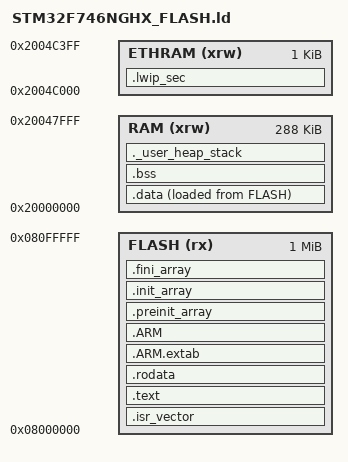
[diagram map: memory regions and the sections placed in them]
/*
******************************************************************************
**
** @file        : LinkerScript.ld
**
** @author      : Auto-generated by STM32CubeIDE
**
**  Abstract    : Linker script for STM32F746G-DISCO Board embedding STM32F746NGHx Device from stm32f7 series
**                      1024KBytes FLASH
**                      320KBytes RAM
**
**                Set heap size, stack size and stack location according
**                to application requirements.
**
**                Set memory bank area and size if external memory is used
**
**  Target      : STMicroelectronics STM32
**
**  Distribution: The file is distributed as is, without any warranty
**                of any kind.
**
******************************************************************************
** @attention
**
** Copyright (c) 2026 STMicroelectronics.
** All rights reserved.
**
** This software is licensed under terms that can be found in the LICENSE file
** in the root directory of this software component.
** If no LICENSE file comes with this software, it is provided AS-IS.
**
******************************************************************************
*/

/* Entry Point */
ENTRY(Reset_Handler)

/* Highest address of the user mode stack */
/* Main stack (MSP: startup + ISRs) stays at the very top of SRAM2 and grows
   down toward the ETH descriptors at 0x2004C000 (~15 KB of headroom, same
   layout as ST's LwIP examples). Kept OUT of the linker regions below. */
_estack = 0x20050000;

_Min_Heap_Size = 0x1000; /* required amount of heap (printf/newlib under FreeRTOS) */
_Min_Stack_Size = 0x400; /* required amount of stack */

/* Memories definition.
   The top 32 KB of the 320 KB RAM are reserved outside the linker regions:
     0x20048000..0x2004BFFF  LwIP heap (LWIP_RAM_HEAP_POINTER, MPU
                             non-cacheable so ETH DMA reads TX pbufs
                             coherently with the D-cache enabled)
     0x2004C000..0x2004C3FF  ETH DMA descriptors (ETHRAM below, MPU device)
     0x2004C400..0x2004FFFF  main stack (MSP), growing down from _estack */
MEMORY
{
  RAM    (xrw)    : ORIGIN = 0x20000000,   LENGTH = 288K
  ETHRAM (xrw)    : ORIGIN = 0x2004C000,   LENGTH = 1K
  FLASH    (rx)    : ORIGIN = 0x8000000,   LENGTH = 1024K
}

/* Sections */
SECTIONS
{

  /* The startup code into "FLASH" Rom type memory */
  .isr_vector :
  {
    . = ALIGN(4);
    KEEP(*(.isr_vector)) /* Startup code */
    . = ALIGN(4);
  } >FLASH

  /* The program code and other data into "FLASH" Rom type memory */
  .text :
  {
    . = ALIGN(4);
    *(.text)           /* .text sections (code) */
    *(.text*)          /* .text* sections (code) */
    *(.glue_7)         /* glue arm to thumb code */
    *(.glue_7t)        /* glue thumb to arm code */
    *(.eh_frame)

    KEEP (*(.init))
    KEEP (*(.fini))

    . = ALIGN(4);
    _etext = .;        /* define a global symbols at end of code */
  } >FLASH

  /* Constant data into "FLASH" Rom type memory */
  .rodata :
  {
    . = ALIGN(4);
    *(.rodata)         /* .rodata sections (constants, strings, etc.) */
    *(.rodata*)        /* .rodata* sections (constants, strings, etc.) */
    . = ALIGN(4);
  } >FLASH

  .ARM.extab (READONLY) : /* The "READONLY" keyword is only supported in GCC11 and later, remove it if using GCC10 or earlier. */
  {
    . = ALIGN(4);
    *(.ARM.extab* .gnu.linkonce.armextab.*)
    . = ALIGN(4);
  } >FLASH

  .ARM (READONLY) : /* The "READONLY" keyword is only supported in GCC11 and later, remove it if using GCC10 or earlier. */
  {
    . = ALIGN(4);
    __exidx_start = .;
    *(.ARM.exidx*)
    __exidx_end = .;
    . = ALIGN(4);
  } >FLASH

  .preinit_array (READONLY) : /* The "READONLY" keyword is only supported in GCC11 and later, remove it if using GCC10 or earlier. */
  {
    . = ALIGN(4);
    PROVIDE_HIDDEN (__preinit_array_start = .);
    KEEP (*(.preinit_array*))
    PROVIDE_HIDDEN (__preinit_array_end = .);
    . = ALIGN(4);
  } >FLASH

  .init_array (READONLY) : /* The "READONLY" keyword is only supported in GCC11 and later, remove it if using GCC10 or earlier. */
  {
    . = ALIGN(4);
    PROVIDE_HIDDEN (__init_array_start = .);
    KEEP (*(SORT(.init_array.*)))
    KEEP (*(.init_array*))
    PROVIDE_HIDDEN (__init_array_end = .);
    . = ALIGN(4);
  } >FLASH

  .fini_array (READONLY) : /* The "READONLY" keyword is only supported in GCC11 and later, remove it if using GCC10 or earlier. */
  {
    . = ALIGN(4);
    PROVIDE_HIDDEN (__fini_array_start = .);
    KEEP (*(SORT(.fini_array.*)))
    KEEP (*(.fini_array*))
    PROVIDE_HIDDEN (__fini_array_end = .);
    . = ALIGN(4);
  } >FLASH

  /* Used by the startup to initialize data */
  _sidata = LOADADDR(.data);

  /* Initialized data sections into "RAM" Ram type memory */
  .data :
  {
    . = ALIGN(4);
    _sdata = .;        /* create a global symbol at data start */
    *(.data)           /* .data sections */
    *(.data*)          /* .data* sections */
    *(.RamFunc)        /* .RamFunc sections */
    *(.RamFunc*)       /* .RamFunc* sections */

    . = ALIGN(4);
    _edata = .;        /* define a global symbol at data end */

  } >RAM AT> FLASH

  /* Uninitialized data section into "RAM" Ram type memory */
  . = ALIGN(4);
  .bss :
  {
    /* This is used by the startup in order to initialize the .bss section */
    _sbss = .;         /* define a global symbol at bss start */
    __bss_start__ = _sbss;
    *(.bss)
    *(.bss*)
    *(COMMON)

    . = ALIGN(4);
    _ebss = .;         /* define a global symbol at bss end */
    __bss_end__ = _ebss;
  } >RAM

  /* Ethernet DMA descriptors (GCC). ethernetif.c places DMARxDscrTab /
     DMATxDscrTab into these sections. Fixed at 0x2004C000 (ETHRAM) and
     covered by an MPU device region so they stay coherent with the ETH DMA
     now that the D-cache is on. NOLOAD: HAL_ETH_Init initializes them. */
  .lwip_sec (NOLOAD) :
  {
    . = ALIGN(4);
    *(.RxDecripSection)
    *(.TxDecripSection)
    *(.RxArraySection)
    . = ALIGN(4);
  } >ETHRAM

  /* User_heap_stack section, used to check that there is enough "RAM" Ram  type memory left */
  ._user_heap_stack :
  {
    . = ALIGN(8);
    PROVIDE ( end = . );
    PROVIDE ( _end = . );
    . = . + _Min_Heap_Size;
    . = . + _Min_Stack_Size;
    . = ALIGN(8);
  } >RAM

  /* Remove information from the compiler libraries */
  /DISCARD/ :
  {
    libc.a ( * )
    libm.a ( * )
    libgcc.a ( * )
  }

  .ARM.attributes 0 : { *(.ARM.attributes) }
}
